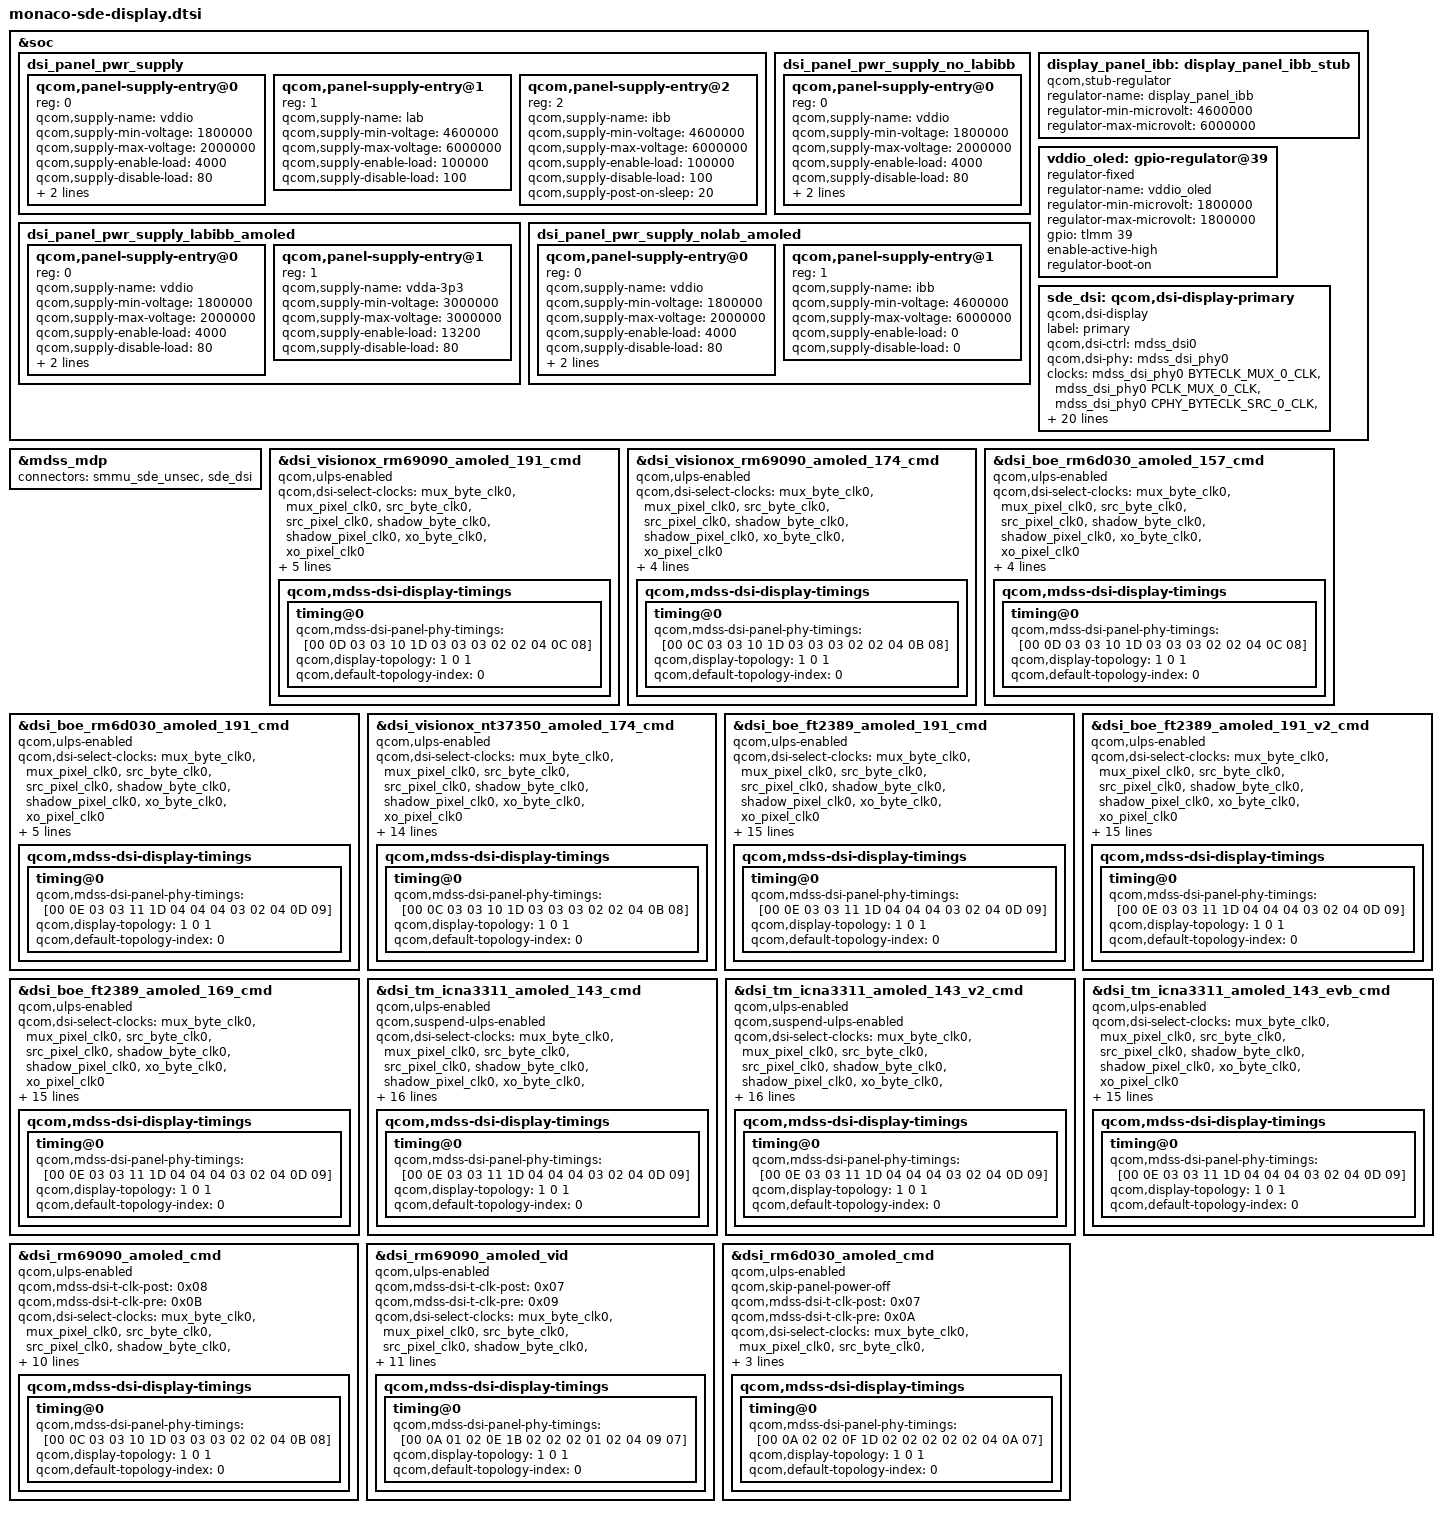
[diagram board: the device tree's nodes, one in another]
#include <dt-bindings/clock/qcom,rpmcc.h>
#include <dt-bindings/clock/mdss-5nm-pll-clk.h>
#include "dsi-panel-rm69090-amoled-178-cmd.dtsi"
#include "dsi-panel-rm69090-amoled-178-vid.dtsi"
#include "dsi-panel-rm6d030-amoled-141-cmd.dtsi"
#include "dsi-panel-rm69090-amoled-191-cmd.dtsi"
#include "dsi-panel-rm69090-amoled-174-cmd.dtsi"
#include "dsi-panel-rm6d030-amoled-157-cmd.dtsi"
#include "dsi-panel-rm6d030-amoled-191-cmd.dtsi"
#include "dsi-panel-nt37350-amoled-174-cmd.dtsi"
#include "dsi-panel-ft2389-amoled-191-cmd.dtsi"
#include "dsi-panel-ft2389-amoled-191-v2-cmd.dtsi"
#include "dsi-panel-ft2389-amoled-169-cmd.dtsi"
#include "dsi-panel-icna3311-amoled-143-cmd.dtsi"
#include "dsi-panel-icna3311-amoled-143-v2-cmd.dtsi"
#include "dsi-panel-icna3311-amoled-143-evb-cmd.dtsi"


&soc {
	dsi_panel_pwr_supply: dsi_panel_pwr_supply {
		#address-cells = <1>;
		#size-cells = <0>;

		qcom,panel-supply-entry@0 {
			reg = <0>;
			qcom,supply-name = "vddio";
			qcom,supply-min-voltage = <1800000>;
			qcom,supply-max-voltage = <2000000>;
			qcom,supply-enable-load = <4000>;
			qcom,supply-disable-load = <80>;
			qcom,supply-ulp-load = <100>;
			qcom,supply-post-on-sleep = <20>;
		};

		qcom,panel-supply-entry@1 {
			reg = <1>;
			qcom,supply-name = "lab";
			qcom,supply-min-voltage = <4600000>;
			qcom,supply-max-voltage = <6000000>;
			qcom,supply-enable-load = <100000>;
			qcom,supply-disable-load = <100>;
		};

		qcom,panel-supply-entry@2 {
			reg = <2>;
			qcom,supply-name = "ibb";
			qcom,supply-min-voltage = <4600000>;
			qcom,supply-max-voltage = <6000000>;
			qcom,supply-enable-load = <100000>;
			qcom,supply-disable-load = <100>;
			qcom,supply-post-on-sleep = <20>;
		};
	};

	dsi_panel_pwr_supply_no_labibb: dsi_panel_pwr_supply_no_labibb {
		#address-cells = <1>;
		#size-cells = <0>;

		qcom,panel-supply-entry@0 {
			reg = <0>;
			qcom,supply-name = "vddio";
			qcom,supply-min-voltage = <1800000>;
			qcom,supply-max-voltage = <2000000>;
			qcom,supply-enable-load = <4000>;
			qcom,supply-disable-load = <80>;
			qcom,supply-ulp-load = <100>;
			qcom,supply-post-on-sleep = <0>;
		};
	};

	dsi_panel_pwr_supply_labibb_amoled: dsi_panel_pwr_supply_labibb_amoled {
		#address-cells = <1>;
		#size-cells = <0>;

		qcom,panel-supply-entry@0 {
			reg = <0>;
			qcom,supply-name = "vddio";
			qcom,supply-min-voltage = <1800000>;
			qcom,supply-max-voltage = <2000000>;
			qcom,supply-enable-load = <4000>;
			qcom,supply-disable-load = <80>;
			qcom,supply-ulp-load = <100>;
			qcom,supply-post-on-sleep = <20>;
		};

		qcom,panel-supply-entry@1 {
			reg = <1>;
			qcom,supply-name = "vdda-3p3";
			qcom,supply-min-voltage = <3000000>;
			qcom,supply-max-voltage = <3000000>;
			qcom,supply-enable-load = <13200>;
			qcom,supply-disable-load = <80>;
		};
	};

	dsi_panel_pwr_supply_nolab_amoled: dsi_panel_pwr_supply_nolab_amoled {
		#address-cells = <1>;
		#size-cells = <0>;

		qcom,panel-supply-entry@0 {
			reg = <0>;
			qcom,supply-name = "vddio";
			qcom,supply-min-voltage = <1800000>;
			qcom,supply-max-voltage = <2000000>;
			qcom,supply-enable-load = <4000>;
			qcom,supply-disable-load = <80>;
			qcom,supply-ulp-load = <100>;
			qcom,supply-post-on-sleep = <20>;
		};

		qcom,panel-supply-entry@1 {
			reg = <1>;
			qcom,supply-name = "ibb";
			qcom,supply-min-voltage = <4600000>;
			qcom,supply-max-voltage = <6000000>;
			qcom,supply-enable-load = <0>;
			qcom,supply-disable-load = <0>;
		};
	};

	display_panel_ibb: display_panel_ibb_stub {
		compatible = "qcom,stub-regulator";
		regulator-name = "display_panel_ibb";
		regulator-min-microvolt = <4600000>;
		regulator-max-microvolt = <6000000>;
	};

	vddio_oled: gpio-regulator@39 {
		compatible = "regulator-fixed";
		regulator-name = "vddio_oled";
		regulator-min-microvolt = <1800000>;
		regulator-max-microvolt = <1800000>;
		gpio = <&tlmm 39 0x0>;
		enable-active-high;
		regulator-boot-on;
	};

	sde_dsi: qcom,dsi-display-primary {
		compatible = "qcom,dsi-display";
		label = "primary";
		qcom,dsi-ctrl = <&mdss_dsi0>;
		qcom,dsi-phy = <&mdss_dsi_phy0>;

		clocks = <&mdss_dsi_phy0 BYTECLK_MUX_0_CLK>,
			 <&mdss_dsi_phy0 PCLK_MUX_0_CLK>,
			 <&mdss_dsi_phy0 CPHY_BYTECLK_SRC_0_CLK>,
			 <&mdss_dsi_phy0 CPHY_PCLK_SRC_0_CLK>,
			 <&mdss_dsi_phy0 BYTECLK_SRC_0_CLK>,
			 <&mdss_dsi_phy0 PCLK_SRC_0_CLK>,
			 <&mdss_dsi_phy0 SHADOW_BYTECLK_SRC_0_CLK>,
			 <&mdss_dsi_phy0 SHADOW_PCLK_SRC_0_CLK>,
			 <&mdss_dsi_phy0 SHADOW_CPHY_BYTECLK_SRC_0_CLK>,
			 <&mdss_dsi_phy0 SHADOW_CPHY_PCLK_SRC_0_CLK>,
			 <&rpmcc RPM_SMD_XO_CLK_SRC>,
			 <&rpmcc RPM_SMD_XO_CLK_SRC>;
		clock-names = "mux_byte_clk0", "mux_pixel_clk0",
			"cphy_byte_clk0", "cphy_pixel_clk0",
			"src_byte_clk0", "src_pixel_clk0",
			"shadow_byte_clk0", "shadow_pixel_clk0",
			"shadow_cphybyte_clk0", "shadow_cphypixel_clk0",
			"xo_byte_clk0", "xo_pixel_clk0";
		pinctrl-names = "panel_active", "panel_suspend";
		pinctrl-0 = <&sde_dsi_active &sde_te_active>;
		pinctrl-1 = <&sde_dsi_suspend &sde_te_suspend>;

		qcom,platform-te-gpio = <&tlmm 73 0>;
		qcom,panel-te-source = <0>;
		qcom,needs-clk-src-reset;
		qcom,needs-ctrl-vreg-disable;
		vddio-supply = <&vddio_oled>;
		/*vddio-supply = <&L21A>;*/
		ibb-supply = <&display_panel_ibb>;
		qcom,mdp = <&mdss_mdp>;

		qcom,dsi-default-panel =
			<&dsi_visionox_rm69090_amoled_191_cmd>;
	};
};

&mdss_mdp {
	  connectors = <&smmu_sde_unsec &sde_dsi>;
};

&dsi_visionox_rm69090_amoled_191_cmd {
	qcom,ulps-enabled;
	/*qcom,mdss-dsi-t-clk-post = <0x05>;*/
	/*qcom,mdss-dsi-t-clk-pre = <0x16>;*/
	qcom,dsi-select-clocks = "mux_byte_clk0", "mux_pixel_clk0",
				"src_byte_clk0", "src_pixel_clk0",
				"shadow_byte_clk0", "shadow_pixel_clk0",
				"xo_byte_clk0", "xo_pixel_clk0";

	qcom,panel-supply-entries = <&dsi_panel_pwr_supply_no_labibb>;
	qcom,platform-reset-gpio = <&pm5100_gpios 2 0>;
	qcom,platform-en-gpio = <&pm5100_gpios 1 0>;
	qcom,platform-vci3p3-en-gpio = <&tlmm 23 0>;

	qcom,mdss-dsi-display-timings {
		timing@0 {
			qcom,mdss-dsi-panel-phy-timings = [00 0D 03 03 10 1D 03
				03 03 02 02 04 0C 08];
			qcom,display-topology = <1 0 1>;
			qcom,default-topology-index = <0>;
		};
	};
};

&dsi_visionox_rm69090_amoled_174_cmd {
	qcom,ulps-enabled;
	/*qcom,mdss-dsi-t-clk-post = <0x05>;*/
	/*qcom,mdss-dsi-t-clk-pre = <0x16>;*/
	qcom,dsi-select-clocks = "mux_byte_clk0", "mux_pixel_clk0",
				"src_byte_clk0", "src_pixel_clk0",
				"shadow_byte_clk0", "shadow_pixel_clk0",
				"xo_byte_clk0", "xo_pixel_clk0";

	qcom,panel-supply-entries = <&dsi_panel_pwr_supply_no_labibb>;
	qcom,platform-reset-gpio = <&pm5100_gpios 2 0>;
	qcom,platform-en-gpio = <&pm5100_gpios 1 0>;

	qcom,mdss-dsi-display-timings {
		timing@0 {
			qcom,mdss-dsi-panel-phy-timings = [00 0C 03 03 10 1D 03
				03 03 02 02 04 0B 08];
			qcom,display-topology = <1 0 1>;
			qcom,default-topology-index = <0>;
		};
	};
};

&dsi_boe_rm6d030_amoled_157_cmd {
	qcom,ulps-enabled;
	/*qcom,mdss-dsi-t-clk-post = <0x05>;*/
	/*qcom,mdss-dsi-t-clk-pre = <0x16>;*/
	qcom,dsi-select-clocks = "mux_byte_clk0", "mux_pixel_clk0",
				"src_byte_clk0", "src_pixel_clk0",
				"shadow_byte_clk0", "shadow_pixel_clk0";

	qcom,panel-supply-entries = <&dsi_panel_pwr_supply_no_labibb>;
	qcom,platform-reset-gpio = <&pm5100_gpios 2 0>;
	qcom,platform-en-gpio = <&pm5100_gpios 1 0>;

	qcom,mdss-dsi-display-timings {
		timing@0 {
			qcom,mdss-dsi-panel-phy-timings = [00 0B 02 02 0F 1C 03
				02 02 02 02 04 0A 07];
			qcom,display-topology = <1 0 1>;
			qcom,default-topology-index = <0>;
		};
	};
};

&dsi_boe_rm6d030_amoled_191_cmd {
	qcom,ulps-enabled;
	/*qcom,mdss-dsi-t-clk-post = <0x05>;*/
	/*qcom,mdss-dsi-t-clk-pre = <0x16>;*/
	qcom,dsi-select-clocks = "mux_byte_clk0", "mux_pixel_clk0",
				"src_byte_clk0", "src_pixel_clk0",
				"shadow_byte_clk0", "shadow_pixel_clk0",
				"xo_byte_clk0", "xo_pixel_clk0";

	qcom,panel-supply-entries = <&dsi_panel_pwr_supply_no_labibb>;
	qcom,platform-reset-gpio = <&pm5100_gpios 2 0>;
	qcom,platform-en-gpio = <&pm5100_gpios 1 0>;
	qcom,platform-vci3p3-en-gpio = <&tlmm 23 0>;

	qcom,mdss-dsi-display-timings {
		timing@0 {
			qcom,mdss-dsi-panel-phy-timings = [00 0E 03 03 11 1D 04
				04 04 03 02 04 0D 09];
			qcom,display-topology = <1 0 1>;
			qcom,default-topology-index = <0>;
		};
	};
};

&dsi_visionox_nt37350_amoled_174_cmd {
	qcom,ulps-enabled;
	/*qcom,mdss-dsi-t-clk-post = <0x05>;*/
	/*qcom,mdss-dsi-t-clk-pre = <0x16>;*/
	qcom,dsi-select-clocks = "mux_byte_clk0", "mux_pixel_clk0",
				"src_byte_clk0", "src_pixel_clk0",
				"shadow_byte_clk0", "shadow_pixel_clk0",
				"xo_byte_clk0", "xo_pixel_clk0";

	qcom,mdss-dsi-panel-status-check-mode = "reg_read";
	qcom,mdss-dsi-panel-status-command = [06 01 00 01 00 00 01 0a];
	qcom,mdss-dsi-panel-status-command-state = "dsi_lp_mode";
	qcom,mdss-dsi-panel-status-value = <0x9c 0xdc>;
	qcom,mdss-dsi-panel-status-read-length = <1>;
	qcom,mdss-dsi-panel-max-error-count = <2>;
	qcom,esd-check-enabled;

	qcom,panel-supply-entries = <&dsi_panel_pwr_supply_no_labibb>;
	qcom,platform-reset-gpio = <&pm5100_gpios 2 0>;
	qcom,platform-en-gpio = <&pm5100_gpios 1 0>;

	qcom,mdss-dsi-display-timings {
		timing@0 {
			qcom,mdss-dsi-panel-phy-timings = [00 0C 03 03 10 1D 03
				03 03 02 02 04 0B 08];
			qcom,display-topology = <1 0 1>;
			qcom,default-topology-index = <0>;
		};
	};
};

&dsi_boe_ft2389_amoled_191_cmd {
	qcom,ulps-enabled;
	qcom,dsi-select-clocks = "mux_byte_clk0", "mux_pixel_clk0",
				"src_byte_clk0", "src_pixel_clk0",
				"shadow_byte_clk0", "shadow_pixel_clk0",
				"xo_byte_clk0", "xo_pixel_clk0";
	qcom,mdss-dsi-panel-status-check-mode = "reg_read";
	qcom,mdss-dsi-panel-status-command = [06 01 00 01 00 00 01 0a];
	qcom,mdss-dsi-panel-status-command-state = "dsi_lp_mode";
	qcom,mdss-dsi-panel-status-value = <0x9c 0xdc>;
	qcom,mdss-dsi-panel-status-read-length = <1>;
	qcom,mdss-dsi-panel-max-error-count = <2>;
	qcom,esd-check-enabled;

	qcom,panel-supply-entries = <&dsi_panel_pwr_supply_no_labibb>;
	qcom,platform-reset-gpio = <&pm5100_gpios 2 0>;
	qcom,platform-en-gpio = <&pm5100_gpios 1 0>;
	qcom,platform-vci3p3-en-gpio = <&tlmm 23 0>;

	qcom,mdss-dsi-display-timings {
		timing@0 {
			qcom,mdss-dsi-panel-phy-timings = [00 0E 03 03 11 1D 04
				04 04 03 02 04 0D 09];
			qcom,display-topology = <1 0 1>;
			qcom,default-topology-index = <0>;
		};
	};
};

&dsi_boe_ft2389_amoled_191_v2_cmd {
	qcom,ulps-enabled;
	qcom,dsi-select-clocks = "mux_byte_clk0", "mux_pixel_clk0",
				"src_byte_clk0", "src_pixel_clk0",
				"shadow_byte_clk0", "shadow_pixel_clk0",
				"xo_byte_clk0", "xo_pixel_clk0";
	qcom,mdss-dsi-panel-status-check-mode = "reg_read";
	qcom,mdss-dsi-panel-status-command = [06 01 00 01 00 00 01 0a];
	qcom,mdss-dsi-panel-status-command-state = "dsi_lp_mode";
	qcom,mdss-dsi-panel-status-value = <0x9c 0xdc>;
	qcom,mdss-dsi-panel-status-read-length = <1>;
	qcom,mdss-dsi-panel-max-error-count = <2>;
	qcom,esd-check-enabled;

	qcom,panel-supply-entries = <&dsi_panel_pwr_supply_no_labibb>;
	qcom,platform-reset-gpio = <&pm5100_gpios 2 0>;
	qcom,platform-en-gpio = <&pm5100_gpios 1 0>;
	qcom,platform-vci3p3-en-gpio = <&tlmm 23 0>;

	qcom,mdss-dsi-display-timings {
		timing@0 {
			qcom,mdss-dsi-panel-phy-timings = [00 0E 03 03 11 1D 04
				04 04 03 02 04 0D 09];
			qcom,display-topology = <1 0 1>;
			qcom,default-topology-index = <0>;
		};
	};
};

&dsi_boe_ft2389_amoled_169_cmd {
	qcom,ulps-enabled;
	qcom,dsi-select-clocks = "mux_byte_clk0", "mux_pixel_clk0",
				"src_byte_clk0", "src_pixel_clk0",
				"shadow_byte_clk0", "shadow_pixel_clk0",
				"xo_byte_clk0", "xo_pixel_clk0";
	qcom,mdss-dsi-panel-status-check-mode = "reg_read";
	qcom,mdss-dsi-panel-status-command = [06 01 00 01 00 00 01 0a];
	qcom,mdss-dsi-panel-status-command-state = "dsi_lp_mode";
	qcom,mdss-dsi-panel-status-value = <0x9c 0xdc>;
	qcom,mdss-dsi-panel-status-read-length = <1>;
	qcom,mdss-dsi-panel-max-error-count = <2>;
	qcom,esd-check-enabled;

	qcom,panel-supply-entries = <&dsi_panel_pwr_supply_no_labibb>;
	qcom,platform-reset-gpio = <&pm5100_gpios 2 0>;
	qcom,platform-en-gpio = <&pm5100_gpios 1 0>;
	qcom,platform-vci3p3-en-gpio = <&tlmm 23 0>;

	qcom,mdss-dsi-display-timings {
		timing@0 {
			qcom,mdss-dsi-panel-phy-timings = [00 0E 03 03 11 1D 04
				04 04 03 02 04 0D 09];
			qcom,display-topology = <1 0 1>;
			qcom,default-topology-index = <0>;
		};
	};
};

&dsi_tm_icna3311_amoled_143_cmd {
	qcom,ulps-enabled;
	qcom,suspend-ulps-enabled;
	qcom,dsi-select-clocks = "mux_byte_clk0", "mux_pixel_clk0",
				"src_byte_clk0", "src_pixel_clk0",
				"shadow_byte_clk0", "shadow_pixel_clk0",
				"xo_byte_clk0", "xo_pixel_clk0";
	qcom,mdss-dsi-panel-status-check-mode = "reg_read";
	qcom,mdss-dsi-panel-status-command = [06 01 00 01 00 00 01 0a];
	qcom,mdss-dsi-panel-status-command-state = "dsi_lp_mode";
	qcom,mdss-dsi-panel-status-value = <0x9c 0xdc>;
	qcom,mdss-dsi-panel-status-read-length = <1>;
	qcom,mdss-dsi-panel-max-error-count = <2>;
	qcom,esd-check-enabled;

	qcom,panel-supply-entries = <&dsi_panel_pwr_supply_no_labibb>;
	qcom,platform-reset-gpio = <&pm5100_gpios 2 0>;
	qcom,platform-en-gpio = <&pm5100_gpios 1 0>;
	qcom,platform-vci3p3-en-gpio = <&tlmm 23 0>;

	qcom,mdss-dsi-display-timings {
		timing@0 {
			qcom,mdss-dsi-panel-phy-timings = [00 0E 03 03 11 1D 04
				04 04 03 02 04 0D 09];
			qcom,display-topology = <1 0 1>;
			qcom,default-topology-index = <0>;
		};
	};
};

&dsi_tm_icna3311_amoled_143_v2_cmd {
	qcom,ulps-enabled;
	qcom,suspend-ulps-enabled;
	qcom,dsi-select-clocks = "mux_byte_clk0", "mux_pixel_clk0",
				"src_byte_clk0", "src_pixel_clk0",
				"shadow_byte_clk0", "shadow_pixel_clk0",
				"xo_byte_clk0", "xo_pixel_clk0";
	qcom,mdss-dsi-panel-status-check-mode = "reg_read";
	qcom,mdss-dsi-panel-status-command = [06 01 00 01 00 00 01 0a];
	qcom,mdss-dsi-panel-status-command-state = "dsi_lp_mode";
	qcom,mdss-dsi-panel-status-value = <0x9c 0xdc>;
	qcom,mdss-dsi-panel-status-read-length = <1>;
	qcom,mdss-dsi-panel-max-error-count = <2>;
	qcom,esd-check-enabled;

	qcom,panel-supply-entries = <&dsi_panel_pwr_supply_no_labibb>;
	qcom,platform-reset-gpio = <&pm5100_gpios 2 0>;
	qcom,platform-en-gpio = <&pm5100_gpios 1 0>;
	qcom,platform-vci3p3-en-gpio = <&tlmm 23 0>;

	qcom,mdss-dsi-display-timings {
		timing@0 {
			qcom,mdss-dsi-panel-phy-timings = [00 0E 03 03 11 1D 04
				04 04 03 02 04 0D 09];
			qcom,display-topology = <1 0 1>;
			qcom,default-topology-index = <0>;
		};
	};
};

&dsi_tm_icna3311_amoled_143_evb_cmd {
	qcom,ulps-enabled;
	qcom,dsi-select-clocks = "mux_byte_clk0", "mux_pixel_clk0",
				"src_byte_clk0", "src_pixel_clk0",
				"shadow_byte_clk0", "shadow_pixel_clk0",
				"xo_byte_clk0", "xo_pixel_clk0";
	qcom,mdss-dsi-panel-status-check-mode = "reg_read";
	qcom,mdss-dsi-panel-status-command = [06 01 00 01 00 00 01 0a];
	qcom,mdss-dsi-panel-status-command-state = "dsi_lp_mode";
	qcom,mdss-dsi-panel-status-value = <0x9c 0xdc>;
	qcom,mdss-dsi-panel-status-read-length = <1>;
	qcom,mdss-dsi-panel-max-error-count = <2>;
	qcom,esd-check-enabled;

	qcom,panel-supply-entries = <&dsi_panel_pwr_supply_no_labibb>;
	qcom,platform-reset-gpio = <&pm5100_gpios 2 0>;
	qcom,platform-en-gpio = <&pm5100_gpios 1 0>;
	qcom,platform-vci3p3-en-gpio = <&tlmm 23 0>;

	qcom,mdss-dsi-display-timings {
		timing@0 {
			qcom,mdss-dsi-panel-phy-timings = [00 0E 03 03 11 1D 04
				04 04 03 02 04 0D 09];
			qcom,display-topology = <1 0 1>;
			qcom,default-topology-index = <0>;
		};
	};
};

&dsi_rm69090_amoled_cmd {
	qcom,ulps-enabled;
	qcom,mdss-dsi-t-clk-post = <0x08>;
	qcom,mdss-dsi-t-clk-pre = <0x0B>;
	qcom,dsi-select-clocks = "mux_byte_clk0", "mux_pixel_clk0",
				"src_byte_clk0", "src_pixel_clk0",
				"shadow_byte_clk0", "shadow_pixel_clk0",
				"xo_byte_clk0", "xo_pixel_clk0";

	qcom,mdss-dsi-panel-status-check-mode = "reg_read";
	qcom,mdss-dsi-panel-status-command = [06 01 00 01 00 00 01 0a];
	qcom,mdss-dsi-panel-status-command-state = "dsi_lp_mode";
	qcom,mdss-dsi-panel-status-value = <0x9c>;
	qcom,mdss-dsi-panel-status-read-length = <1>;

	qcom,mdss-dsi-display-timings {
		timing@0 {
			qcom,mdss-dsi-panel-phy-timings = [00 0C 03 03 10 1D 03
				03 03 02 02 04 0B 08];
			qcom,display-topology = <1 0 1>;
			qcom,default-topology-index = <0>;
		};
	};
};

&dsi_boe_rm6d030_amoled_157_cmd {
	qcom,ulps-enabled;
	/*qcom,mdss-dsi-t-clk-post = <0x05>;*/
	/*qcom,mdss-dsi-t-clk-pre = <0x16>;*/
	qcom,dsi-select-clocks = "mux_byte_clk0", "mux_pixel_clk0",
				"src_byte_clk0", "src_pixel_clk0",
				"shadow_byte_clk0", "shadow_pixel_clk0",
				"xo_byte_clk0", "xo_pixel_clk0";

	qcom,panel-supply-entries = <&dsi_panel_pwr_supply_no_labibb>;
	qcom,platform-reset-gpio = <&pm5100_gpios 2 0>;
	qcom,platform-en-gpio = <&pm5100_gpios 1 0>;

	qcom,mdss-dsi-display-timings {
		timing@0 {
			/*qcom,mdss-dsi-panel-phy-timings = [00 0B 02 02 0F 1C 03
				02 02 02 02 04 0A 07];*/
			qcom,mdss-dsi-panel-phy-timings = [00 0D 03 03 10 1D 03
				03 03 02 02 04 0C 08];
			qcom,display-topology = <1 0 1>;
			qcom,default-topology-index = <0>;
		};
	};
};

&dsi_rm69090_amoled_vid {
	qcom,ulps-enabled;
	qcom,mdss-dsi-t-clk-post = <0x07>;
	qcom,mdss-dsi-t-clk-pre = <0x09>;
	qcom,dsi-select-clocks = "mux_byte_clk0", "mux_pixel_clk0",
				"src_byte_clk0", "src_pixel_clk0",
				"shadow_byte_clk0", "shadow_pixel_clk0",
				"xo_byte_clk0", "xo_pixel_clk0";

	qcom,mdss-dsi-panel-status-check-mode = "reg_read";
	qcom,mdss-dsi-panel-status-command = [06 01 00 01 00 00 01 0a];
	qcom,mdss-dsi-panel-status-command-state = "dsi_lp_mode";
	qcom,mdss-dsi-panel-status-value = <0x9c>;
	qcom,mdss-dsi-panel-status-read-length = <1>;
	qcom,esd-check-enabled;

	qcom,mdss-dsi-display-timings {
		timing@0 {
			qcom,mdss-dsi-panel-phy-timings = [00 0A 01 02 0E 1B 02
				02 02 01 02 04 09 07];
			qcom,display-topology = <1 0 1>;
			qcom,default-topology-index = <0>;
		};
	};
};

&dsi_rm6d030_amoled_cmd {
	qcom,ulps-enabled;
	qcom,skip-panel-power-off;
	qcom,mdss-dsi-t-clk-post = <0x07>;
	qcom,mdss-dsi-t-clk-pre = <0x0A>;
	qcom,dsi-select-clocks = "mux_byte_clk0", "mux_pixel_clk0",
				"src_byte_clk0", "src_pixel_clk0",
				"shadow_byte_clk0", "shadow_pixel_clk0",
				"xo_byte_clk0", "xo_pixel_clk0";

	qcom,mdss-dsi-display-timings {
		timing@0 {
			qcom,mdss-dsi-panel-phy-timings = [00 0A 02 02 0F 1D 02
				02 02 02 02 04 0A 07];
			qcom,display-topology = <1 0 1>;
			qcom,default-topology-index = <0>;
		};
	};
};
